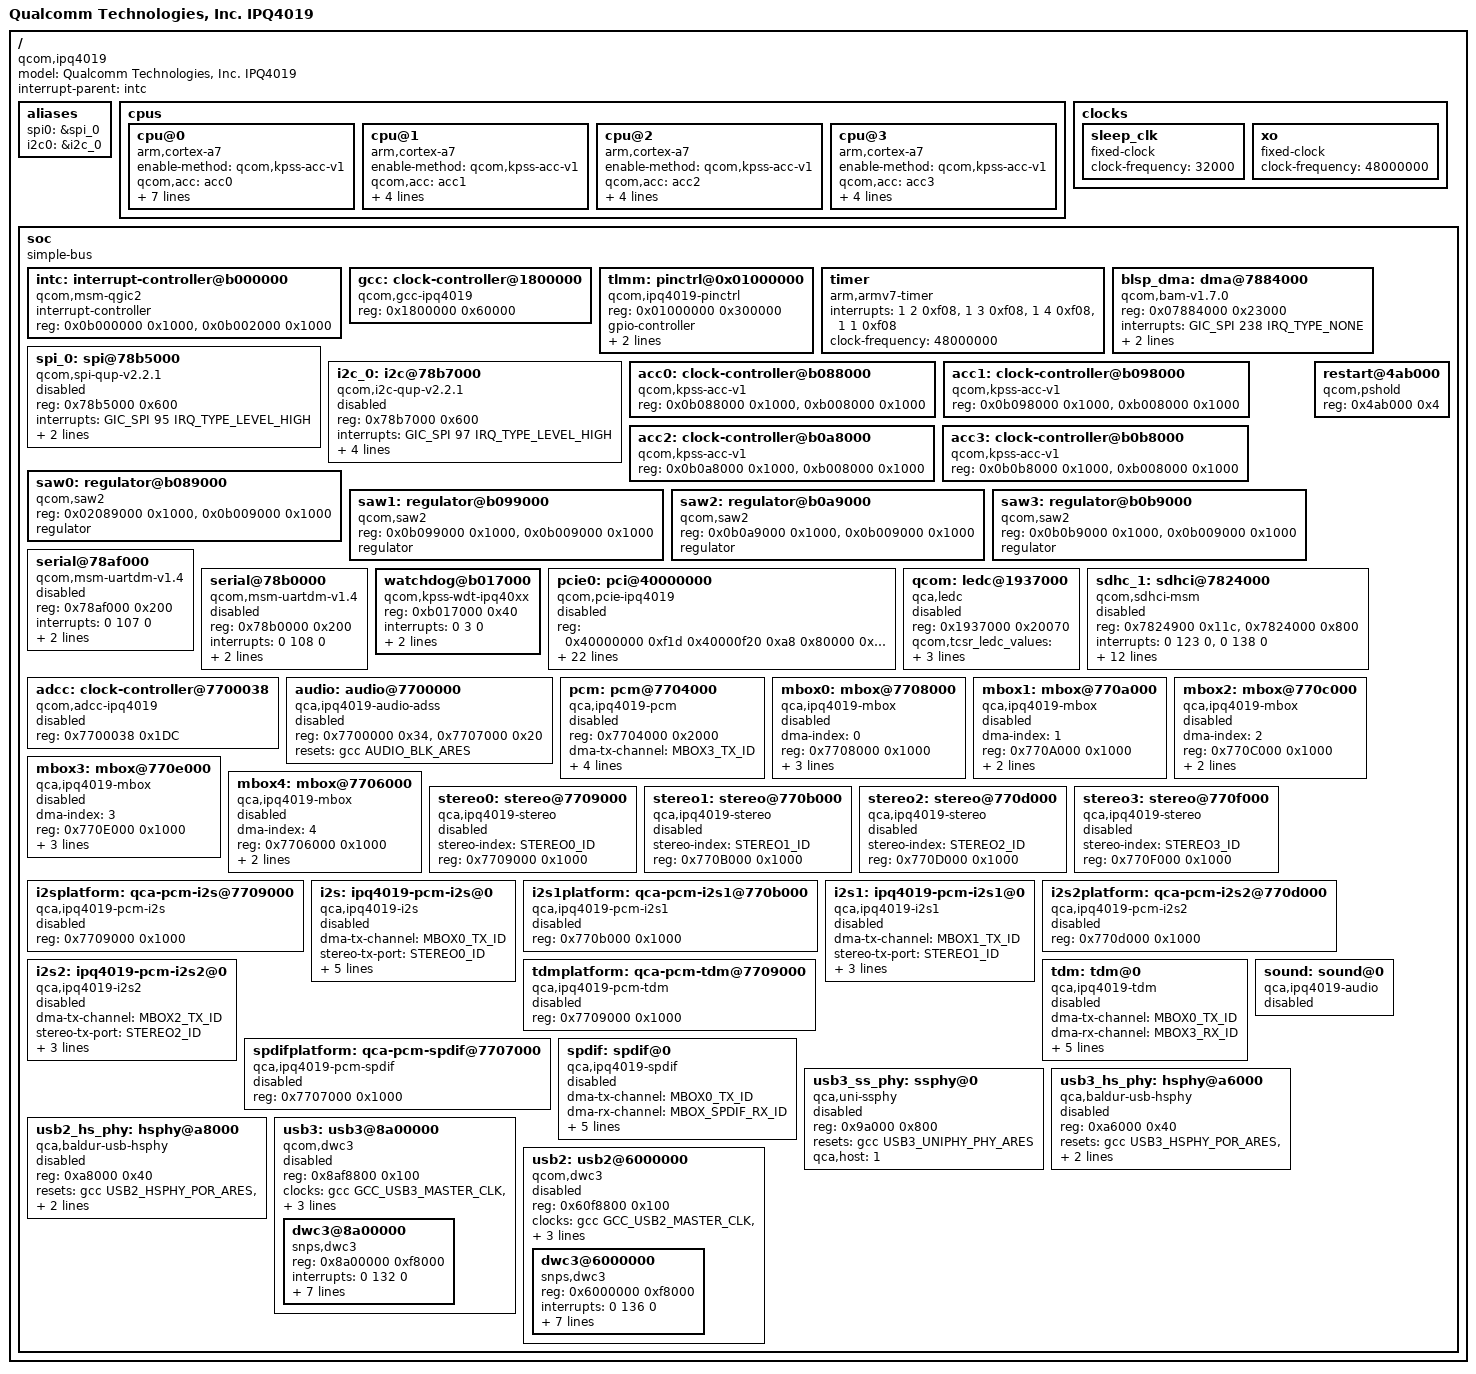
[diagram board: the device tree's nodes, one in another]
/*
 * Copyright (c) 2015 - 2016, The Linux Foundation. All rights reserved.
 *
 * Permission to use, copy, modify, and/or distribute this software for any
 * purpose with or without fee is hereby granted, provided that the above
 * copyright notice and this permission notice appear in all copies.
 *
 * THE SOFTWARE IS PROVIDED "AS IS" AND THE AUTHOR DISCLAIMS ALL WARRANTIES
 * WITH REGARD TO THIS SOFTWARE INCLUDING ALL IMPLIED WARRANTIES OF
 * MERCHANTABILITY AND FITNESS. IN NO EVENT SHALL THE AUTHOR BE LIABLE FOR
 * ANY SPECIAL, DIRECT, INDIRECT, OR CONSEQUENTIAL DAMAGES OR ANY DAMAGES
 * WHATSOEVER RESULTING FROM LOSS OF USE, DATA OR PROFITS, WHETHER IN AN
 * ACTION OF CONTRACT, NEGLIGENCE OR OTHER TORTIOUS ACTION, ARISING OUT OF
 * OR IN CONNECTION WITH THE USE OR PERFORMANCE OF THIS SOFTWARE.
 */

/dts-v1/;

#include "skeleton.dtsi"
#include <dt-bindings/clock/qcom,gcc-ipq4019.h>
#include <dt-bindings/clock/qca,adcc-ipq4019.h>
#include <dt-bindings/sound/ipq4019-audio.h>
#include <dt-bindings/interrupt-controller/arm-gic.h>
#include <dt-bindings/interrupt-controller/irq.h>

/ {
	model = "Qualcomm Technologies, Inc. IPQ4019";
	compatible = "qcom,ipq4019";
	interrupt-parent = <&intc>;

	aliases {
		spi0 = &spi_0;
		i2c0 = &i2c_0;
	};

	cpus {
		#address-cells = <1>;
		#size-cells = <0>;
		cpu@0 {
			device_type = "cpu";
			compatible = "arm,cortex-a7";
			enable-method = "qcom,kpss-acc-v1";
			qcom,acc = <&acc0>;
			qcom,saw = <&saw0>;
			reg = <0x0>;
			clocks = <&gcc GCC_APPS_CLK_SRC>;
			clock-frequency = <0>;
			operating-points = <
				/* kHz	uV (fixed) */
				48000	1100000
				200000	1100000
				500000	1100000
				666000	1100000
			>;
			clock-latency = <100000>;
		};

		cpu@1 {
			device_type = "cpu";
			compatible = "arm,cortex-a7";
			enable-method = "qcom,kpss-acc-v1";
			qcom,acc = <&acc1>;
			qcom,saw = <&saw1>;
			reg = <0x1>;
			clocks = <&gcc GCC_APPS_CLK_SRC>;
			clock-frequency = <0>;
		};

		cpu@2 {
			device_type = "cpu";
			compatible = "arm,cortex-a7";
			enable-method = "qcom,kpss-acc-v1";
			qcom,acc = <&acc2>;
			qcom,saw = <&saw2>;
			reg = <0x2>;
			clocks = <&gcc GCC_APPS_CLK_SRC>;
			clock-frequency = <0>;
		};

		cpu@3 {
			device_type = "cpu";
			compatible = "arm,cortex-a7";
			enable-method = "qcom,kpss-acc-v1";
			qcom,acc = <&acc3>;
			qcom,saw = <&saw3>;
			reg = <0x3>;
			clocks = <&gcc GCC_APPS_CLK_SRC>;
			clock-frequency = <0>;
		};
	};

	clocks {
		sleep_clk: sleep_clk {
			compatible = "fixed-clock";
			clock-frequency = <32000>;
			#clock-cells = <0>;
		};
		xo: xo {
			compatible = "fixed-clock";
			clock-frequency = <48000000>;
			#clock-cells = <0>;
		};
	};

	soc {
		#address-cells = <1>;
		#size-cells = <1>;
		ranges;
		compatible = "simple-bus";

		intc: interrupt-controller@b000000 {
			compatible = "qcom,msm-qgic2";
			interrupt-controller;
			#interrupt-cells = <3>;
			reg = <0x0b000000 0x1000>,
			<0x0b002000 0x1000>;
		};

		gcc: clock-controller@1800000 {
			compatible = "qcom,gcc-ipq4019";
			#clock-cells = <1>;
			#reset-cells = <1>;
			reg = <0x1800000 0x60000>;
		};

		tlmm: pinctrl@0x01000000 {
			compatible = "qcom,ipq4019-pinctrl";
			reg = <0x01000000 0x300000>;
			gpio-controller;
			#gpio-cells = <2>;
			interrupt-controller;
			#interrupt-cells = <2>;
			interrupts = <0 208 0>;
		};

		timer {
			compatible = "arm,armv7-timer";
			interrupts = <1 2 0xf08>,
				     <1 3 0xf08>,
				     <1 4 0xf08>,
				     <1 1 0xf08>;
			clock-frequency = <48000000>;
		};

		blsp_dma: dma@7884000 {
			compatible = "qcom,bam-v1.7.0";
			reg = <0x07884000 0x23000>;
			interrupts = <GIC_SPI 238 IRQ_TYPE_NONE>;
			clocks = <&gcc GCC_BLSP1_AHB_CLK>;
			clock-names = "bam_clk";
			#dma-cells = <1>;
			qcom,ee = <0>;
			status = "ok";
		};

		spi_0: spi@78b5000 {
			compatible = "qcom,spi-qup-v2.2.1";
			reg = <0x78b5000 0x600>;
			interrupts = <GIC_SPI 95 IRQ_TYPE_LEVEL_HIGH>;
			clocks = <&gcc GCC_BLSP1_QUP1_SPI_APPS_CLK>,
				 <&gcc GCC_BLSP1_AHB_CLK>;
			clock-names = "core", "iface";
			#address-cells = <1>;
			#size-cells = <0>;
			status = "disabled";
		};

		i2c_0: i2c@78b7000 { /* BLSP1 QUP3 */
			compatible = "qcom,i2c-qup-v2.2.1";
			#address-cells = <1>;
			#size-cells = <0>;
			reg = <0x78b7000 0x600>;
			interrupts = <GIC_SPI 97 IRQ_TYPE_LEVEL_HIGH>;
			clocks = <&gcc GCC_BLSP1_AHB_CLK>,
				 <&gcc GCC_BLSP1_QUP1_I2C_APPS_CLK>;
			clock-names = "iface", "core";
			clock-frequency  = <100000>;
			dmas = <&blsp_dma 9>, <&blsp_dma 8>;
			dma-names = "rx", "tx";
			status = "disabled";
		};

		acc0: clock-controller@b088000 {
			compatible = "qcom,kpss-acc-v1";
			reg = <0x0b088000 0x1000>, <0xb008000 0x1000>;
		};

		acc1: clock-controller@b098000 {
			compatible = "qcom,kpss-acc-v1";
			reg = <0x0b098000 0x1000>, <0xb008000 0x1000>;
		};

		acc2: clock-controller@b0a8000 {
			compatible = "qcom,kpss-acc-v1";
			reg = <0x0b0a8000 0x1000>, <0xb008000 0x1000>;
		};

		acc3: clock-controller@b0b8000 {
			compatible = "qcom,kpss-acc-v1";
			reg = <0x0b0b8000 0x1000>, <0xb008000 0x1000>;
		};

		saw0: regulator@b089000 {
			compatible = "qcom,saw2";
			reg = <0x02089000 0x1000>, <0x0b009000 0x1000>;
			regulator;
		};

		saw1: regulator@b099000 {
			compatible = "qcom,saw2";
			reg = <0x0b099000 0x1000>, <0x0b009000 0x1000>;
			regulator;
		};

		saw2: regulator@b0a9000 {
			compatible = "qcom,saw2";
			reg = <0x0b0a9000 0x1000>, <0x0b009000 0x1000>;
			regulator;
		};

		saw3: regulator@b0b9000 {
			compatible = "qcom,saw2";
			reg = <0x0b0b9000 0x1000>, <0x0b009000 0x1000>;
			regulator;
		};

		serial@78af000 {
			compatible = "qcom,msm-uartdm-v1.4", "qcom,msm-uartdm";
			reg = <0x78af000 0x200>;
			interrupts = <0 107 0>;
			status = "disabled";
			clocks = <&gcc GCC_BLSP1_UART1_APPS_CLK>,
				<&gcc GCC_BLSP1_AHB_CLK>;
			clock-names = "core", "iface";
		};

		serial@78b0000 {
			compatible = "qcom,msm-uartdm-v1.4", "qcom,msm-uartdm";
			reg = <0x78b0000 0x200>;
			interrupts = <0 108 0>;
			status = "disabled";
			clocks = <&gcc GCC_BLSP1_UART2_APPS_CLK>,
				<&gcc GCC_BLSP1_AHB_CLK>;
			clock-names = "core", "iface";
		};

		watchdog@b017000 {
			compatible = "qcom,kpss-wdt-ipq40xx";
			reg = <0xb017000 0x40>;
			interrupt-names = "bark_irq";
			interrupts = <0 3 0>;
			clocks = <&sleep_clk>;
			timeout-sec = <10>;
			status = "ok";
		};

		pcie0: pci@40000000 {
			compatible = "qcom,pcie-ipq4019";
			reg =  <0x40000000 0xf1d
				0x40000f20 0xa8
				0x80000 0x2000
				0x40100000 0x1000>;
			reg-names = "dbi", "elbi", "parf", "config";
			device_type = "pci";
			linux,pci-domain = <0>;
			bus-range = <0x00 0xff>;
			num-lanes = <1>;
			#address-cells = <3>;
			#size-cells = <2>;

			ranges = <0x81000000 0 0x40200000 0x40200000
				  0 0x00100000   /* downstream I/O */
				  0x82000000 0 0x40300000 0x40300000
				  0 0x00d00000>; /* non-prefetchable memory */

			interrupts = <0 142 0>;
			interrupt-names = "msi";
			#interrupt-cells = <1>;
			interrupt-map-mask = <0 0 0 0x7>;
			interrupt-map = <0 0 0 1 &intc 0 143
					 IRQ_TYPE_LEVEL_HIGH>, /* int_a */
					<0 0 0 2 &intc 0 144
					 IRQ_TYPE_LEVEL_HIGH>, /* int_b */
					<0 0 0 3 &intc 0 145
					 IRQ_TYPE_LEVEL_HIGH>, /* int_c */
					<0 0 0 4 &intc 0 146
					 IRQ_TYPE_LEVEL_HIGH>; /* int_d */
			clocks = <&gcc GCC_PCIE_AHB_CLK>,
				 <&gcc GCC_PCIE_AXI_M_CLK>,
				 <&gcc GCC_PCIE_AXI_S_CLK>;
			clock-names = "ahb",
				      "axi_m",
				      "axi_s";

			resets = <&gcc PCIE_AXI_M_ARES>,
				 <&gcc PCIE_AXI_S_ARES>,
				 <&gcc PCIE_PIPE_ARES>,
				 <&gcc PCIE_AXI_M_VMIDMT_ARES>,
				 <&gcc PCIE_AXI_S_XPU_ARES>,
				 <&gcc PCIE_PARF_XPU_ARES>,
				 <&gcc PCIE_PHY_ARES>,
				 <&gcc PCIE_AXI_M_STICKY_ARES>,
				 <&gcc PCIE_PIPE_STICKY_ARES>,
				 <&gcc PCIE_PWR_ARES>,
				 <&gcc PCIE_AHB_ARES>,
				 <&gcc PCIE_PHY_AHB_ARES>;
			reset-names = "axi_m",
				      "axi_s",
				      "pipe",
				      "axi_m_vmid",
				      "axi_s_xpu",
				      "parf",
				      "phy",
				      "axi_m_sticky",
				      "pipe_sticky",
				      "pwr",
				      "ahb",
				      "phy_ahb";

			status = "disabled";
		};

		qcom: ledc@1937000  {
			compatible = "qca,ledc";
			reg = <0x1937000 0x20070>;
			reg-names = "ledc_base_addr";
			qcom,tcsr_ledc_values = <0x320193 0x14720800 0x20d 0x0 \
				0x0 0xFFFFFFFF 0x0 0x7 0x7D0010 0x0 \
				0x10482090 0x3FFFDFC>;
			qcom,ledc_blink_indices_cnt = <0>;
			qcom,ledc_blink_indices = <0>;
			status = "disabled";
		};

		restart@4ab000 {
			compatible = "qcom,pshold";
			reg = <0x4ab000 0x4>;
		};

		sdhc_1: sdhci@7824000 {
			compatible = "qcom,sdhci-msm";
			reg = <0x7824900 0x11c>, <0x7824000 0x800>;
			reg-names = "hc_mem", "core_mem";
			interrupts = <0 123 0>, <0 138 0>;
			interrupt-names = "hc_irq", "pwr_irq";
			qcom,bus-width = <8>;
			qcom,max_clk = <193000000>;
			clocks = <&gcc GCC_SDCC1_APPS_CLK>,
				 <&gcc GCC_SDCC1_AHB_CLK>;
			clock-names = "core_clk", "iface_clk";

			/* device core power supply */
			qcom,vdd-lpm-sup;
			qcom,vdd-voltage-level = <2900000 2900000>;
			qcom,vdd-current-level = <200 570000>;

			/* device communication power supply */
			qcom,vdd-io-lpm-sup;
			qcom,vdd-io-voltage-level = <1800000 1800000>;
			qcom,vdd-io-current-level = <200 325000>;
			qcom,vdd-io-always-on;


			qcom,large-address-bus;
			status = "disabled";
		};

		adcc: clock-controller@7700038 {
			compatible = "qcom,adcc-ipq4019";
			#clock-cells = <1>;
			#reset-cells = <1>;
			reg = <0x7700038 0x1DC>;
			status = "disabled";
		};

		audio: audio@7700000 {
			compatible = "qca,ipq4019-audio-adss";
			reg = <0x7700000 0x34>,
				<0x7707000 0x20>;
			resets = <&gcc AUDIO_BLK_ARES>;
			reset-names = "blk_rst";
			status = "disabled";
		};

		pcm: pcm@7704000 {
			compatible = "qca,ipq4019-pcm";
			reg = <0x7704000 0x2000>;
			dma-tx-channel = <MBOX3_TX_ID>;
			dma-rx-channel = <MBOX0_RX_ID>;
			stereo-tx-port = <STEREO3_ID>;
			stereo-rx-port = <STEREO0_ID>;
			clocks = <&adcc ADCC_PCM_CLK_SRC>;
			clock-names = "audio_pcm_clk";
			status = "disabled";
		};

		mbox0: mbox@7708000 {
			dma-index = <0>;
			compatible = "qca,ipq4019-mbox";
			reg = <0x7708000 0x1000>;
			interrupts = <0 156 0>;
			tx-channel = <MBOX0_TX_ID>;
			rx-channel = <MBOX0_RX_ID>;
			status = "disabled";
		};

		mbox1: mbox@770a000 {
			dma-index = <1>;
			compatible = "qca,ipq4019-mbox";
			reg = <0x770A000 0x1000>;
			interrupts = <0 157 0>;
			tx-channel = <MBOX1_TX_ID>;
			status = "disabled";
		};

		mbox2: mbox@770c000 {
			dma-index = <2>;
			compatible = "qca,ipq4019-mbox";
			reg = <0x770C000 0x1000>;
			interrupts = <0 158 0>;
			tx-channel = <MBOX2_TX_ID>;
			status = "disabled";
		};

		mbox3: mbox@770e000 {
			dma-index = <3>;
			compatible = "qca,ipq4019-mbox";
			reg = <0x770E000 0x1000>;
			interrupts = <0 159 0>;
			tx-channel = <MBOX3_TX_ID>;
			rx-channel = <MBOX3_RX_ID>;
			status = "disabled";
		};

		mbox4: mbox@7706000 {
			dma-index = <4>;
			compatible = "qca,ipq4019-mbox";
			reg = <0x7706000 0x1000>;
			interrupts = <0 163 0>;
			rx-channel = <MBOX_SPDIF_RX_ID>;
			status = "disabled";
		};

		stereo0: stereo@7709000 {
			stereo-index = <STEREO0_ID>;
			compatible = "qca,ipq4019-stereo";
			reg = <0x7709000 0x1000>;
			status = "disabled";
		};

		stereo1: stereo@770b000 {
			stereo-index = <STEREO1_ID>;
			compatible = "qca,ipq4019-stereo";
			reg = <0x770B000 0x1000>;
			status = "disabled";
		};

		stereo2: stereo@770d000 {
			stereo-index = <STEREO2_ID>;
			compatible = "qca,ipq4019-stereo";
			reg = <0x770D000 0x1000>;
			status = "disabled";
		};

		stereo3: stereo@770f000 {
			stereo-index = <STEREO3_ID>;
			compatible = "qca,ipq4019-stereo";
			reg = <0x770F000 0x1000>;
			status = "disabled";
		};

		i2splatform: qca-pcm-i2s@7709000 {
			compatible = "qca,ipq4019-pcm-i2s";
			reg = <0x7709000 0x1000>;
			status = "disabled";
		};

		i2s: ipq4019-pcm-i2s@0 {
			compatible = "qca,ipq4019-i2s";
			dma-tx-channel = <MBOX0_TX_ID>;
			stereo-tx-port = <STEREO0_ID>;
			dma-rx-channel = <MBOX3_RX_ID>;
			stereo-rx-port = <STEREO3_ID>;
			clocks = <&adcc ADCC_TXB_CLK_SRC>,
				<&adcc ADCC_TXM_CLK_SRC>,
				<&adcc ADCC_RXB_CLK_SRC>,
				<&adcc ADCC_RXM_CLK_SRC>;
			clock-names = "audio_tx_bclk",
				"audio_tx_mclk",
				"audio_rx_bclk",
				"audio_rx_mclk";
			status = "disabled";
		};

		i2s1platform: qca-pcm-i2s1@770b000 {
			compatible = "qca,ipq4019-pcm-i2s1";
			reg = <0x770b000 0x1000>;
			status = "disabled";
		};

		i2s1: ipq4019-pcm-i2s1@0 {
			compatible = "qca,ipq4019-i2s1";
			dma-tx-channel = <MBOX1_TX_ID>;
			stereo-tx-port = <STEREO1_ID>;
			clocks = <&adcc ADCC_TXB_CLK_SRC>,
				<&adcc ADCC_TXM_CLK_SRC>,
				<&adcc ADCC_RXB_CLK_SRC>,
				<&adcc ADCC_RXM_CLK_SRC>;
			clock-names = "audio_tx_bclk",
				"audio_tx_mclk",
				"audio_rx_bclk",
				"audio_rx_mclk";
			status = "disabled";
		};

		i2s2platform: qca-pcm-i2s2@770d000 {
			compatible = "qca,ipq4019-pcm-i2s2";
			reg = <0x770d000 0x1000>;
			status = "disabled";
		};

		i2s2: ipq4019-pcm-i2s2@0 {
			compatible = "qca,ipq4019-i2s2";
			dma-tx-channel = <MBOX2_TX_ID>;
			stereo-tx-port = <STEREO2_ID>;
			clocks = <&adcc ADCC_TXB_CLK_SRC>,
				<&adcc ADCC_TXM_CLK_SRC>,
				<&adcc ADCC_RXB_CLK_SRC>,
				<&adcc ADCC_RXM_CLK_SRC>;
			clock-names = "audio_tx_bclk",
				"audio_tx_mclk",
				"audio_rx_bclk",
				"audio_rx_mclk";
			status = "disabled";
		};

		tdmplatform: qca-pcm-tdm@7709000 {
			compatible = "qca,ipq4019-pcm-tdm";
			reg = <0x7709000 0x1000>;
			status = "disabled";
		};

		tdm: tdm@0 {
			compatible = "qca,ipq4019-tdm";
			dma-tx-channel = <MBOX0_TX_ID>;
			dma-rx-channel = <MBOX3_RX_ID>;
			stereo-tx-port = <STEREO0_ID>;
			stereo-rx-port = <STEREO3_ID>;
			clocks = <&adcc ADCC_TXB_CLK_SRC>,
				<&adcc ADCC_TXM_CLK_SRC>,
				<&adcc ADCC_RXB_CLK_SRC>,
				<&adcc ADCC_RXM_CLK_SRC>;
			clock-names = "audio_tx_bclk",
				"audio_tx_mclk",
				"audio_rx_bclk",
				"audio_rx_mclk";
			status = "disabled";
		};

		spdifplatform: qca-pcm-spdif@7707000 {
			compatible = "qca,ipq4019-pcm-spdif";
			reg = <0x7707000 0x1000>;
			status = "disabled";
		};

		spdif: spdif@0 {
			compatible = "qca,ipq4019-spdif";
			dma-tx-channel = <MBOX0_TX_ID>;
			dma-rx-channel = <MBOX_SPDIF_RX_ID>;
			stereo-tx-port = <STEREO0_ID>;
			clocks = <&adcc ADCC_TXB_CLK_SRC>,
				<&adcc ADCC_TXM_CLK_SRC>,
				<&adcc ADCC_SPDIF_SRC>,
				<&adcc ADCC_SPDIFDIV2_SRC >,
				<&adcc ADCC_AUDIO_SPDIFINFAST_SRC>;
			clock-names = "audio_tx_bclk",
				"audio_tx_mclk",
				"audio_spdif_src",
				"audio_spdif_div2",
				"audio_spdifinfast_src";
			status = "disabled";
		};

		sound: sound@0 {
			compatible = "qca,ipq4019-audio";
			status = "disabled";
		};

		usb3_ss_phy: ssphy@0 {
			compatible = "qca,uni-ssphy";
			reg = <0x9a000 0x800>;
			reg-names = "phy_base";
			resets = <&gcc USB3_UNIPHY_PHY_ARES>;
			reset-names = "por_rst";
			qca,host = <1>;
			#phy-cells = <0>;
			status = "disabled";
		};

		usb3_hs_phy: hsphy@a6000 {
			compatible = "qca,baldur-usb-hsphy";
			reg = <0xa6000 0x40>;
			reg-names = "phy_base";
			resets = <&gcc USB3_HSPHY_POR_ARES>,
				<&gcc USB3_HSPHY_S_ARES>;
			reset-names = "por_rst", "srif_rst";
			qca,host = <1>;
			#phy-cells = <0>;
			status = "disabled";
		};

		usb2_hs_phy: hsphy@a8000 {
			compatible = "qca,baldur-usb-hsphy";
			reg = <0xa8000 0x40>;
			reg-names = "phy_base";
			resets = <&gcc USB2_HSPHY_POR_ARES>,
				<&gcc USB2_HSPHY_S_ARES>;
			reset-names = "por_rst", "srif_rst";
			qca,host = <1>;
			#phy-cells = <0>;
			status = "disabled";
		};

		usb3: usb3@8a00000 {
			compatible = "qcom,dwc3";
			#address-cells = <1>;
			#size-cells = <1>;
			ranges;
			reg = <0x8af8800 0x100>;
			reg-names = "qscratch_base";
			clocks = <&gcc GCC_USB3_MASTER_CLK>,
				<&gcc GCC_USB3_SLEEP_CLK>,
				<&gcc GCC_USB3_MOCK_UTMI_CLK>;
			clock-names = "master",
					"sleep",
					"mock_utmi";
			qca,host = <1>;
			status = "disabled";

			dwc3@8a00000 {
				compatible = "snps,dwc3";
				reg = <0x8a00000 0xf8000>;
				interrupts = <0 132 0>;
				#phy-cells = <0>;
				phys = <&usb3_hs_phy>, <&usb3_ss_phy>;
				phy-names = "usb2-phy", "usb3-phy";
				tx-fifo-resize;
				dr_mode = "host";
				usb2-susphy-quirk;
				usb2-host-discon-quirk;
				usb2-host-discon-phy-misc-reg = <0x24>;
				usb2-host-discon-mask = <0x100>;
			};
		};

		usb2: usb2@6000000 {
			compatible = "qcom,dwc3";
			#address-cells = <1>;
			#size-cells = <1>;
			ranges;
			reg = <0x60f8800 0x100>;
			reg-names = "qscratch_base";
			clocks = <&gcc GCC_USB2_MASTER_CLK>,
				<&gcc GCC_USB2_SLEEP_CLK>,
				<&gcc GCC_USB2_MOCK_UTMI_CLK>;
			clock-names = "master",
					"sleep",
					"mock_utmi";
			qca,host = <1>;
			status = "disabled";

			dwc3@6000000 {
				compatible = "snps,dwc3";
				reg = <0x6000000 0xf8000>;
				interrupts = <0 136 0>;
				#phy-cells = <0>;
				phys = <&usb2_hs_phy>;
				phy-names = "usb2-phy";
				tx-fifo-resize;
				dr_mode = "host";
				usb2-susphy-quirk;
				usb2-host-discon-quirk;
				usb2-host-discon-phy-misc-reg = <0x24>;
				usb2-host-discon-mask = <0x100>;
			};
		};
	};
};
